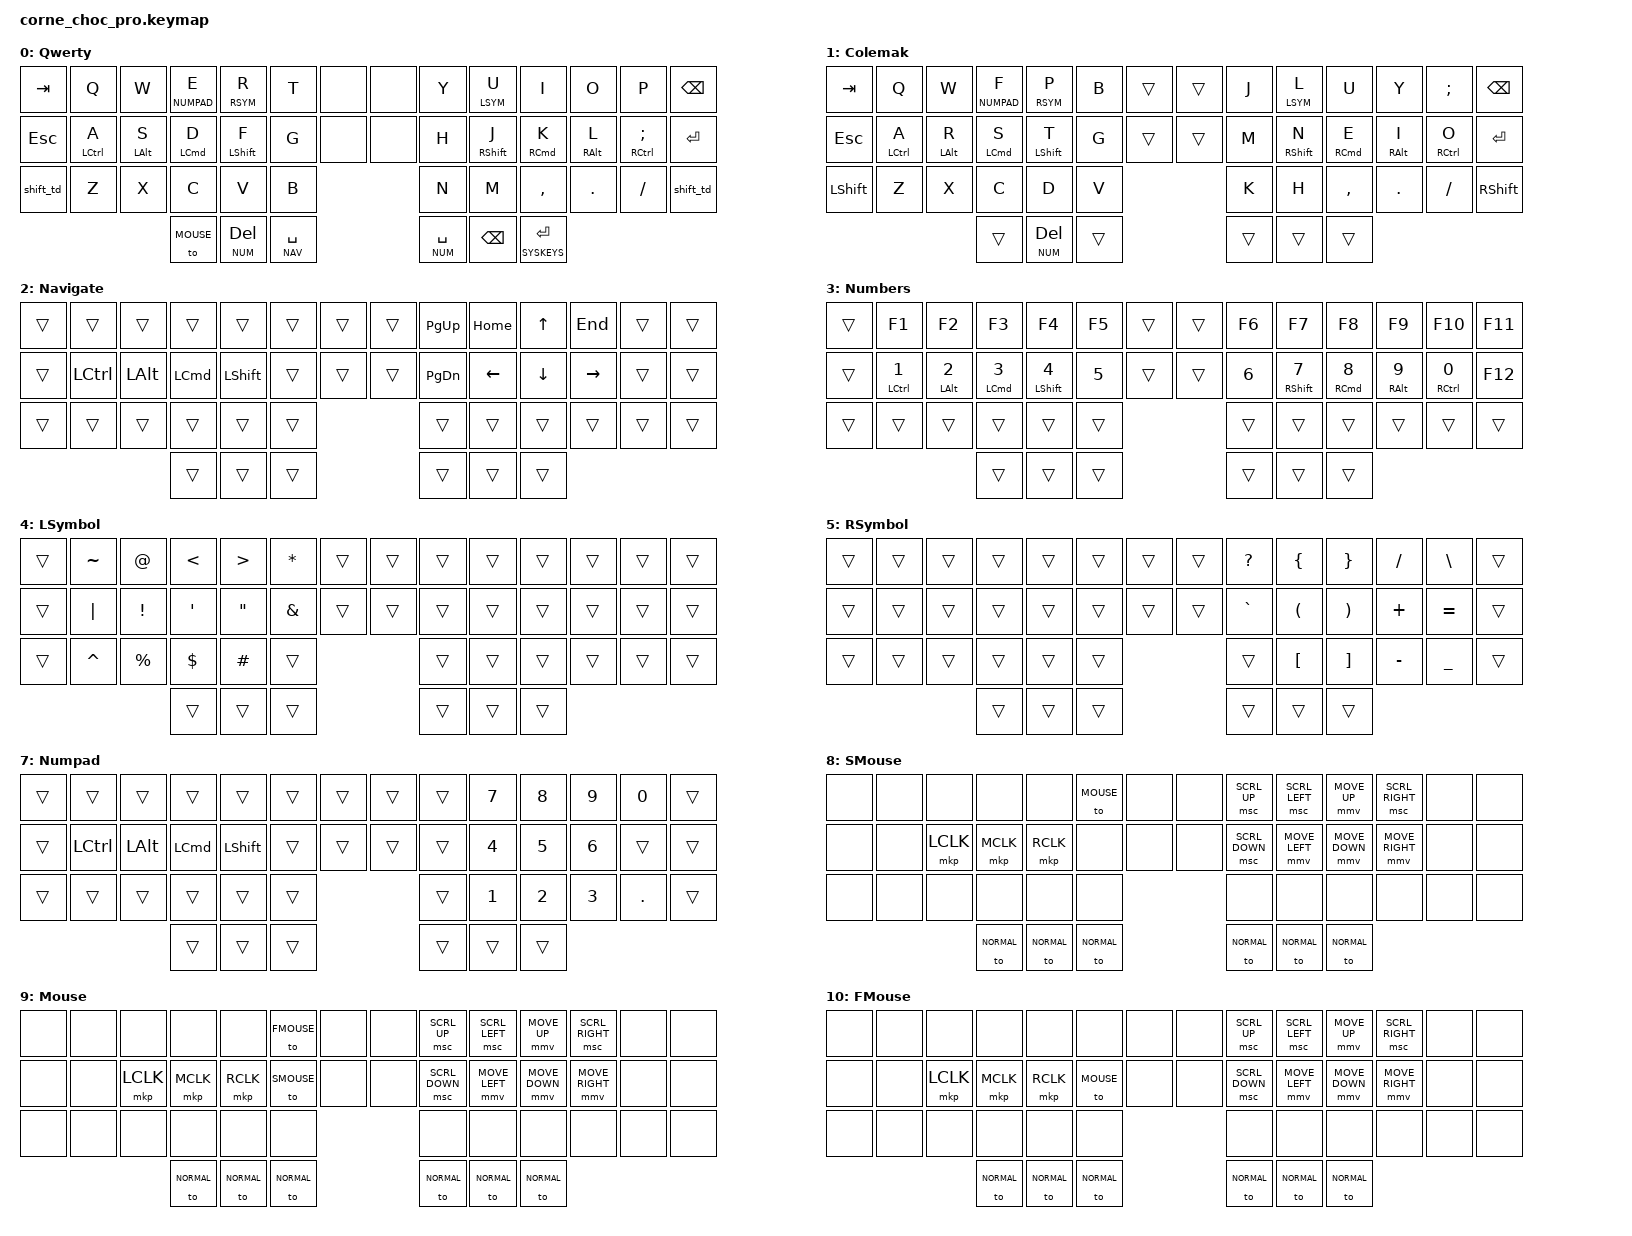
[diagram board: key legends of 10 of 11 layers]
/*
 * Copyright (c) 2020 The ZMK Contributors
 *
 * SPDX-License-Identifier: MIT
 */

#include <behaviors.dtsi>
#include <dt-bindings/zmk/keys.h>
#include <dt-bindings/zmk/bt.h>
#include <dt-bindings/zmk/rgb.h>
#include <input/processors.dtsi>

#define ZMK_POINTING_DEFAULT_SCRL_VAL 15 
#include <dt-bindings/zmk/pointing.h>

#define NORMAL 0
#define COLEMAK 1
#define NAV 2
#define NUM 3
#define LSYM 4
#define RSYM 5
#define SYSKEYS 6
#define NUMPAD 7
#define SMOUSE 8
#define MOUSE 9
#define FMOUSE 10

#define QWERTY_LEFT Q W E R T A S D F G Z X C V B TAB ESC LSHFT
#define QWERTY_RIGHT Y U I O P H J K L SEMI N M COMMA DOT FSLH RET RSHFT BSPC
#define COLEMAK_LEFT Q W F P B A R S T G Z X C D V TAB ESC LSHFT
#define COLEMAK_RIGHT J L U Y SEMI M N E I O K H RET COMMA DOT FSLH RET RSHFT BSPC

&mmv_input_listener {
  warp {
    layers = <FMOUSE>;
    input-processors = <&zip_xy_scaler 2 1>;
  };
  precision {
    layers = <SMOUSE>;
    input-processors = <&zip_xy_scaler 1 2>;
  };
};

&msc_input_listener {
  warp {
    layers = <FMOUSE>;
    input-processors = <&zip_scroll_scaler 2 1>;
  };
  precision {
    layers = <SMOUSE>;
    input-processors = <&zip_scroll_scaler 3 4>;
  };
};

/ {
    chosen {
        zmk,physical-layout = &default_layout;
    };
};

/ {
    behaviors {
        lt: layer_tap {
            compatible = "zmk,behavior-hold-tap";
            #binding-cells = <2>;
            flavor = "tap-preferred";
            tapping-term-ms = <200>;
            bindings = <&mo>, <&kp>;
            display-name = "Layer-Tap";
        };
        // The fast version, for faster fingers
        qlmtf: qwerty_left_mod_tap_fast {
            compatible = "zmk,behavior-hold-tap";
            #binding-cells = <2>;
            flavor = "balanced";
            require-prior-idle-ms = <150>;
            tapping-term-ms = <225>;
            quick-tap-ms = <100>;
            bindings = <&kp>, <&kp>;
            hold-trigger-key-positions = <QWERTY_RIGHT>;
            hold-trigger-on-release;
        };
        // The slower version, for things like my pinkie
        qlmts: qwerty_left_mod_tap_slow {
            compatible = "zmk,behavior-hold-tap";
            #binding-cells = <2>;
            flavor = "balanced";
            require-prior-idle-ms = <150>;
            tapping-term-ms = <225>;
            quick-tap-ms = <150>;
            bindings = <&kp>, <&kp>;
            hold-trigger-key-positions = <QWERTY_RIGHT>;
            hold-trigger-on-release;
        };
        qllt: qwerty_left_layer_tap {
            compatible = "zmk,behavior-hold-tap";
            #binding-cells = <2>;
            flavor = "balanced";
            require-prior-idle-ms = <150>;
            tapping-term-ms = <225>;
            quick-tap-ms = <100>;
            bindings = <&mo>, <&kp>;
            hold-trigger-key-positions = <QWERTY_RIGHT>;
            hold-trigger-on-release;
        };
        qrmtf: qwerty_right_mod_tap_fast {
            compatible = "zmk,behavior-hold-tap";
            #binding-cells = <2>;
            flavor = "balanced";
            require-prior-idle-ms = <150>;
            tapping-term-ms = <225>;
            quick-tap-ms = <100>;
            bindings = <&kp>, <&kp>;
            hold-trigger-key-positions = <QWERTY_LEFT>;
            hold-trigger-on-release;
        };
        qrmts: qwerty_right_mod_tap_slow {
            compatible = "zmk,behavior-hold-tap";
            #binding-cells = <2>;
            flavor = "balanced";
            require-prior-idle-ms = <150>;
            tapping-term-ms = <225>;
            quick-tap-ms = <150>;
            bindings = <&kp>, <&kp>;
            hold-trigger-key-positions = <QWERTY_LEFT>;
            hold-trigger-on-release;
        };
        qrlt: qwerty_right_layer_tap {
            compatible = "zmk,behavior-hold-tap";
            #binding-cells = <2>;
            flavor = "balanced";
            require-prior-idle-ms = <150>;
            tapping-term-ms = <225>;
            quick-tap-ms = <100>;
            bindings = <&mo>, <&kp>;
            hold-trigger-key-positions = <QWERTY_LEFT>;
            hold-trigger-on-release;
        };
        clmt: colemak_left_mod_tap {
            compatible = "zmk,behavior-hold-tap";
            #binding-cells = <2>;
            flavor = "balanced";
            require-prior-idle-ms = <150>;
            tapping-term-ms = <280>;
            quick-tap-ms = <175>;
            bindings = <&kp>, <&kp>;
            hold-trigger-key-positions = <COLEMAK_RIGHT>;
            hold-trigger-on-release;
        };
        cllt: colemak_left_layer_tap {
            compatible = "zmk,behavior-hold-tap";
            #binding-cells = <2>;
            flavor = "balanced";
            require-prior-idle-ms = <150>;
            tapping-term-ms = <280>;
            quick-tap-ms = <175>;
            bindings = <&mo>, <&kp>;
            hold-trigger-key-positions = <COLEMAK_RIGHT>;
            hold-trigger-on-release;
        };
        crmt: colemak_right_mod_tap {
            compatible = "zmk,behavior-hold-tap";
            #binding-cells = <2>;
            flavor = "balanced";
            require-prior-idle-ms = <150>;
            tapping-term-ms = <280>;
            quick-tap-ms = <175>;
            bindings = <&kp>, <&kp>;
            hold-trigger-key-positions = <COLEMAK_LEFT>;
            hold-trigger-on-release;
        };
        crlt: colemak_right_layer_tap {
            compatible = "zmk,behavior-hold-tap";
            #binding-cells = <2>;
            flavor = "balanced";
            require-prior-idle-ms = <150>;
            tapping-term-ms = <280>;
            quick-tap-ms = <175>;
            bindings = <&mo>, <&kp>;
            hold-trigger-key-positions = <COLEMAK_LEFT>;
            hold-trigger-on-release;
        };
        prog_caps: prog_caps {
          compatible = "zmk,behavior-caps-word";
          #binding-cells = <0>;
          continue-list = <UNDERSCORE>;
        };
        shift_td: tap_dance_0 {
          compatible = "zmk,behavior-tap-dance";
          #binding-cells = <0>;
          tapping-term-ms = <200>;
          bindings = <&kp LSHFT>, <&prog_caps>, <&kp CAPS>;
        };
    };
};

/ {
    keymap {
        compatible = "zmk,keymap";

        default_layer {
            display-name = "Qwerty";
            bindings = <
                &kp TAB      &kp Q          &kp W         &qllt NUMPAD E  &qllt   RSYM R &kp T         &none &none &kp Y         &qrlt LSYM U    &kp I           &kp O         &kp P             &kp BSPC
                &kp ESC      &qlmts LCTRL A &qlmts LALT S &qlmtf LCMD D   &qlmtf LSHFT F &kp G         &none &none &kp H         &qrmtf RSHFT J  &qrmtf RCMD K   &qrmts RALT L &qrmts RCTRL SEMI &kp RET
                &shift_td    &kp Z          &kp X         &kp C           &kp V          &kp B                     &kp N         &kp M           &kp COMMA       &kp DOT       &kp FSLH          &shift_td
                                                          &to MOUSE       &lt NUM DEL    &lt NAV SPACE             &lt NUM SPACE &kp BSPC        &lt SYSKEYS RET
            >;
        };
        
        colemak_layer {
            display-name = "Colemak";
            bindings = <
                &kp TAB     &kp Q         &kp W        &cllt NUMPAD F &cllt RSYM P     &kp B  &trans &trans &kp J  &crlt LSYM L  &kp U        &kp Y        &kp SEMI      &kp BSPC
                &kp ESC     &clmt LCTRL A &clmt LALT R &clmt LCMD S   &clmt LSHFT T    &kp G  &trans &trans &kp M  &crmt RSHFT N &crmt RCMD E &crmt RALT I &crmt RCTRL O &kp RET
                &kp LSHFT   &kp Z         &kp X        &kp C          &kp D            &kp V                &kp K  &kp H         &kp COMMA    &kp DOT      &kp FSLH      &kp RSHFT
                                                       &trans         &lt NUM DEL      &trans               &trans &trans        &trans   
            >;
        };

        nav_layer {
            display-name = "Navigate";
            bindings = <
                &trans &trans    &trans   &trans   &trans    &trans  &trans &trans &kp PG_UP &kp HOME &kp UP   &kp END   &trans &trans
                &trans &kp LCTRL &kp LALT &kp LCMD &kp LSHFT &trans  &trans &trans &kp PG_DN &kp LEFT &kp DOWN &kp RIGHT &trans &trans
                &trans &trans    &trans   &trans   &trans    &trans                &trans    &trans   &trans   &trans    &trans &trans
                                          &trans   &trans    &trans                &trans    &trans   &trans 
            >;
        };

        num_layer {
          display-name = "Numbers";
          bindings = <
              &trans &kp F1       &kp F2      &kp F3      &kp F4       &kp F5 &trans &trans &kp F6 &kp F7       &kp F8      &kp F9      &kp F10      &kp F11
              &trans &mt LCTRL N1 &mt LALT N2 &mt LCMD N3 &mt LSHFT N4 &kp N5 &trans &trans &kp N6 &mt RSHFT N7 &mt RCMD N8 &mt RALT N9 &mt RCTRL N0 &kp F12
              &trans &trans       &trans      &trans      &trans       &trans               &trans &trans       &trans      &trans     &trans       &trans
                                              &trans      &trans       &trans               &trans &trans       &trans
          >;
        };

        lsym_layer {
          display-name = "LSymbol";
          bindings = <
              &trans &kp TILDE &kp AT    &kp LT    &kp GT   &kp ASTRK &trans &trans &trans &trans &trans &trans &trans &trans
              &trans &kp PIPE  &kp EXCL  &kp SQT   &kp DQT  &kp AMPS  &trans &trans &trans &trans &trans &trans &trans &trans 
              &trans &kp CARET &kp PRCNT &kp DLLR  &kp HASH &trans                  &trans &trans &trans &trans &trans &trans 
                                         &trans    &trans   &trans                  &trans &trans &trans
          >;
        };

        rsym_layer {
          display-name = "RSymbol";
          bindings = <
              &trans &trans &trans &trans &trans &trans &trans &trans &kp QMARK &kp LBRC &kp RBRC &kp FSLH  &kp BSLH  &trans
              &trans &trans &trans &trans &trans &trans &trans &trans &kp GRAVE &kp LPAR &kp RPAR &kp PLUS  &kp EQUAL &trans
              &trans &trans &trans &trans &trans &trans               &trans    &kp LBKT &kp RBKT &kp MINUS &kp UNDER &trans
                                   &trans &trans &trans               &trans    &trans   &trans
          >;
        };

        syskeys_layer {
          display-name = "Syskeys";
          bindings = <
              &sys_reset  &trans &trans     &kp C_BRI_DN &kp C_BRI_UP &trans &trans &trans &bt BT_SEL 0    &bt BT_SEL 1    &bt BT_SEL 2 &bt BT_SEL 3 &bt BT_SEL 4 &bt BT_CLR
              &bootloader &trans &kp C_PREV &kp C_PP     &kp C_FF     &trans &trans &trans &rgb_ug RGB_TOG &studio_unlock  &trans       &bootloader  &trans       &trans
              &trans      &trans &kp C_MUTE &kp C_VOL_DN &kp C_VOL_UP &trans &trans &trans &trans          &trans          &trans       &trans       &trans       &trans
                                            &trans       &trans       &trans               &trans          &trans          &trans
          >;
        };

        numpad_layer {
          display-name = "Numpad";
          bindings = <
              &trans &trans    &trans   &trans   &trans    &trans  &trans &trans &trans &kp N7 &kp N8 &kp N9 &kp N0  &trans
              &trans &kp LCTRL &kp LALT &kp LCMD &kp LSHFT &trans  &trans &trans &trans &kp N4 &kp N5 &kp N6 &trans  &trans
              &trans &trans    &trans   &trans   &trans    &trans                &trans &kp N1 &kp N2 &kp N3 &kp DOT &trans 
                                        &trans   &trans    &trans                &trans &trans &trans 
          >;
        };

        slow_mouse_layer {
          display-name = "SMouse";
          bindings = <
              &none &none &none     &none      &none      &to MOUSE  &none &none &msc SCRL_UP   &msc SCRL_LEFT &mmv MOVE_UP   &msc SCRL_RIGHT &none &none
              &none &none &mkp LCLK &mkp MCLK  &mkp RCLK  &none      &none &none &msc SCRL_DOWN &mmv MOVE_LEFT &mmv MOVE_DOWN &mmv MOVE_RIGHT &none &none
              &none &none &none     &none      &none      &none                  &none          &none          &none          &none           &none &none
                                    &to NORMAL &to NORMAL &to NORMAL             &to NORMAL     &to NORMAL     &to NORMAL
          >;
        };

        mouse_layer {
          display-name = "Mouse";
          bindings = <
              &none &none &none     &none      &none      &to FMOUSE &none &none &msc SCRL_UP   &msc SCRL_LEFT &mmv MOVE_UP   &msc SCRL_RIGHT &none &none
              &none &none &mkp LCLK &mkp MCLK  &mkp RCLK  &to SMOUSE &none &none &msc SCRL_DOWN &mmv MOVE_LEFT &mmv MOVE_DOWN &mmv MOVE_RIGHT &none &none
              &none &none &none     &none      &none      &none                  &none          &none          &none          &none           &none &none
                                    &to NORMAL &to NORMAL &to NORMAL             &to NORMAL     &to NORMAL     &to NORMAL
          >;
        };

        fast_mouse_layer {
          display-name = "FMouse";
          bindings = <
              &none &none &none     &none      &none      &none      &none &none &msc SCRL_UP   &msc SCRL_LEFT &mmv MOVE_UP   &msc SCRL_RIGHT &none &none
              &none &none &mkp LCLK &mkp MCLK  &mkp RCLK  &to MOUSE  &none &none &msc SCRL_DOWN &mmv MOVE_LEFT &mmv MOVE_DOWN &mmv MOVE_RIGHT &none &none
              &none &none &none     &none      &none      &none                  &none          &none          &none          &none           &none &none
                                    &to NORMAL &to NORMAL &to NORMAL             &to NORMAL     &to NORMAL     &to NORMAL
          >;
        };
    };
};  
